# AM335x register map
Vendor: Texas Instruments; Series: Sitara AM335x; File version: 1.1
CPU: Cortex-A8 r0p0, little endian
Registers are 32-bit, read-write, reset 0x0 unless marked. A register's access mark holds for its fields unless they carry their own. Offsets are from the block's base; [hi:lo] are bit positions; {n}, {i} and the like mark numbered series; 'fields as' and 'values as' point back to an identical list.

## EDMACC — EDMA channel controller module
Base 0x49000000
0x00 PID — PIDCC Register
  [15:0] PID — bits 0..15 (R) Peripheral identifier uniquely identifies the EDMA3CC and the
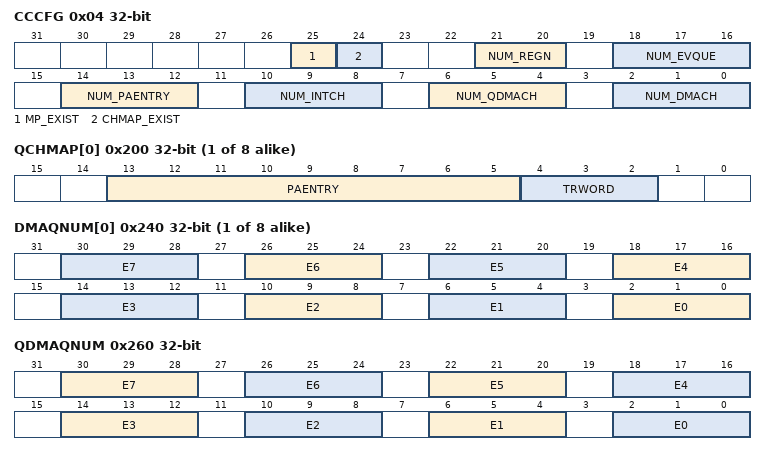
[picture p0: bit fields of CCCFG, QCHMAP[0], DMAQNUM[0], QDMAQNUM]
0x04 CCCFG
  [25] MP_EXIST — bit 25 (R) Memory protection existence
  [24] CHMAP_EXIST — bit 24 (R) Channel map existence
  [21:20] NUM_REGN — bits 20,21 (R) Number of regions
  [18:16] NUM_EVQUE — bits 16..18 (R) Number of event queues
  [14:12] NUM_PAENTRY — bits 12..14 (R) Number of parameter entries
  [10:8] NUM_INTCH — bits 8..10 (R) Number of interrupt channels
  [6:4] NUM_QDMACH — bits 4..6 (R) Number of QDMA channels
  [2:0] NUM_DMACH — bits 0..2 (R) Number of DMA channels
0x10 SYSCONFIG — SYSCONFIGCC Register
  [3:2] IDLEMODE — bits 2,3 (RW) Idle mode configuration [ see e_IDLEMODE]
{0x100+4i} DCHMAP[{i}] (i=0..63) — DMA Channel Mapping Register 0..63
  [13:5] PAENTRY — Parameter entry number
{0x200+4i} QCHMAP[{i}] (i=0..7) — QDMA Channel Mapping Register 0..7
  [13:5] PAENTRY — Parameter entry number
  [4:2] TRWORD — Trigger word selection
{0x240+4i} DMAQNUM[{i}] (i=0..7) — DMA Queue Number Register 0..7
  [4n+2:4n] E{n} (n=0..7)
0x260 QDMAQNUM
  [30:28] E7 — bits 28..30 (RW) Event queue number for QDMA channel 7 [see e_EVENT_QUEUE]
  [26:24] E6 — bits 24..26 (RW) Event queue number for QDMA channel 6 [see e_EVENT_QUEUE]
  [22:20] E5 — bits 20..22 (RW) Event queue number for QDMA channel 5 [see e_EVENT_QUEUE]
  [18:16] E4 — bits 16..18 (RW) Event queue number for QDMA channel 4 [see e_EVENT_QUEUE]
  [14:12] E3 — bits 12..14 (RW) Event queue number for QDMA channel 3 [see e_EVENT_QUEUE]
  [10:8] E2 — bits 8..10 (RW) Event queue number for QDMA channel 2 [see e_EVENT_QUEUE]
  [6:4] E1 — bits 4..6 (RW) Event queue number for QDMA channel 1 [see e_EVENT_QUEUE]
  [2:0] E0 — bits 0..2 (RW) Event queue number for QDMA channel 0 [see e_EVENT_QUEUE]
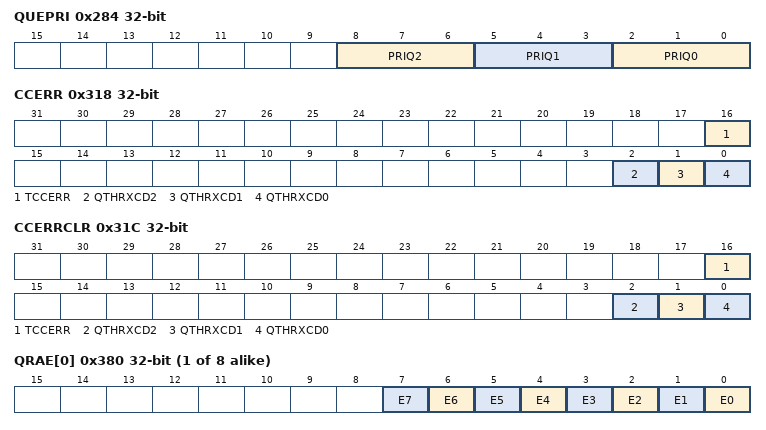
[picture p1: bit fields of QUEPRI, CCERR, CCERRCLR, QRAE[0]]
0x284 QUEPRI
  [8:6] PRIQ2 — bits:8..10 (R/W) Priority level for queue 2. Dictates the priority level used by TC2 relative to other
  [5:3] PRIQ1 — bits:4..6 (R/W) Priority level for queue 1. Dictates the priority level used by TC1 relative to other
  [2:0] PRIQ0 — bits:0..2 (R/W) Priority level for queue 0. Dictates the priority level used by TC0 relative to other
0x300 EMR
  [31:0] En — bits 0..31 (R) Channel 0 to 31 event missed. En is cleared by writing a 1 to the corresponding bit in
0x304 EMRH
  [31:0] En — bits 0..31 (R) Channel 32 to 63 event missed. En is cleared by writing a 1 to the corresponding bit in
0x308 EMCR
  [31:0] En — bits:0..31 (W) Event missed 0 to 31 clear. All error bits must be cleared before additional error
0x30C EMCRH
  [31:0] En — bits:0..31 (W) Event missed 32 to 63 clear. All error bits must be cleared before additional error
0x310 QEMR
  [7:0] En — bits:0..7 (R) Channel 0 to 7 QDMA event missed. En is cleared by writing a 1 to the corresponding bit
0x314 QEMCR
  [7:0] En — bits:0..7 (W) QDMA event missed clear. All error bits must be cleared before additional error
0x318 CCERR
  [16] TCCERR — bit 16 (R) Transfer completion code error
  [2] QTHRXCD2 — bit 2 (R) Queue 2 threshold exceeded error
  [1] QTHRXCD1 — bit 1 (R) Queue 1 threshold exceeded error
  [0] QTHRXCD0 — bit 0 (R) Queue 0 threshold exceeded error
0x31C CCERRCLR
  [16] TCCERR — bit 16 (W) Transfer completion code error clear
  [2] QTHRXCD2 — bit 2 (W) Queue 2 threshold exceeded error clear
  [1] QTHRXCD1 — bit 1 (W) Queue 1 threshold exceeded error clear
  [0] QTHRXCD0 — bit 0 (W) Queue 0 threshold exceeded error clear
0x320 EEVAL
  [0] EVAL — bit 0 (W) Error interrupt evaluate.
{0x340+8i} DRAE{i} (i=0..7) — DRAE Register
  [31:0] En — bits 0..31
{0x344+8i} DRAEH{i} (i=0..7) — DRAEH Register
  [31:0] En — bits:0..31 (R/W) DMA region access enable for bit 63 to 32 in region 0.
{0x380+4i} QRAE[{i}] (i=0..7) — QDMA Region Access Enable Register 0..7
  [n] E{n} (n=0..7) — QDMA channel {n} region access enable
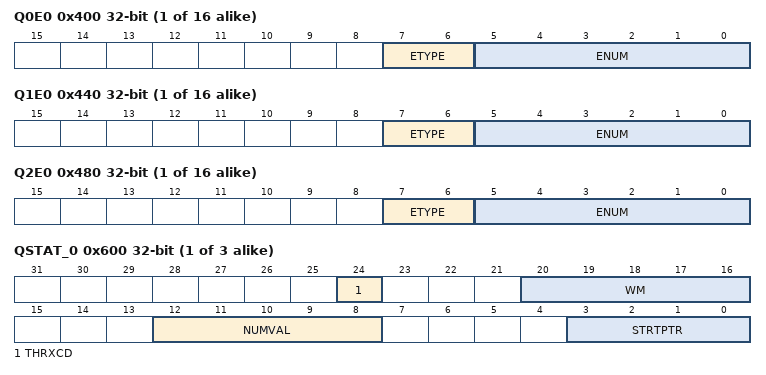
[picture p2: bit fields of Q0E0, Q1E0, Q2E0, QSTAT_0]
{0x400+4i} Q0E{i} (i=0..15) — QmEn Register
  [7:6] ETYPE — bits 6,7 (R) Event entry 0 in queue 1. Specifies the specific event type for the given entry in the
  [5:0] ENUM — bits 0..5 (R) Events entry n(0..15) in queues m(0..3).
{0x440+4i} Q1E{i} (i=0..15) — QmEn Register
  fields as Q0E0
{0x480+4i} Q2E{i} (i=0..15) — QmEn Register
  fields as Q0E0
{0x600+4i} QSTAT_{i} (i=0..2) — QSTAT Register
  [24] THRXCD — bit 24 (R) Threshold crossed.Indicates if the queue threshold was crossed.
  [20:16] WM — bits 16..20 (R) Watermark level.Indicates the watermark level of the queue.
  [12:8] NUMVAL — bits 8..12 (R) Number of valid entries
  [3:0] STRTPTR — bits 0..3 (R) Start pointer.Indicates the start of the queue.
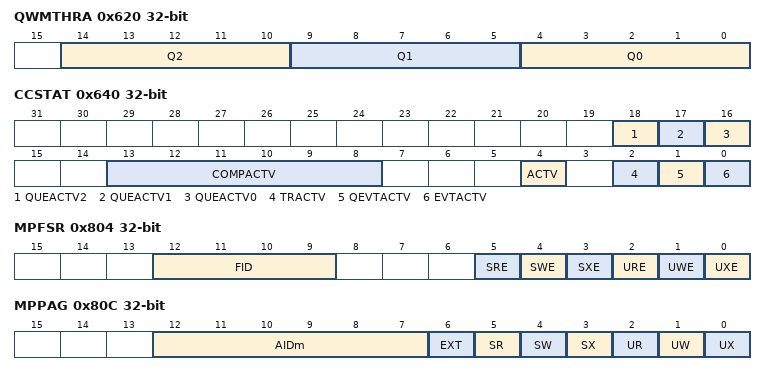
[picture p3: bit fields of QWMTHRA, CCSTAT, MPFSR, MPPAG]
0x620 QWMTHRA
  [14:10] Q2 — bits 16..20 (RW) Watermark threshold for queue 2
  [9:5] Q1 — bits 8..12 (RW) Watermark threshold for queue 1
  [4:0] Q0 — bits 0..4 (RW) Watermark threshold for queue 0
0x640 CCSTAT
  [18] QUEACTV2 — bit 18 (R) Queue 2 active
  [17] QUEACTV1 — bit 17 (R) Queue 1 active
  [16] QUEACTV0 — bit 16 (R) Queue 0 active
  [13:8] COMPACTV — bits 8..13 (R) Completion request active.
  [4] ACTV — bit 4 (R) Channel controller active.
  [2] TRACTV — bit 2 (R) Transfer active
  [1] QEVTACTV — bit 1 (R) QDMA event active
  [0] EVTACTV — bit 0 (R) Event active
0x800 MPFAR
  [31:0] FADDR — bits 0..31 (R) Fault address
0x804 MPFSR
  [12:9] FID — bits 9..12 (R) Faulted identification.
  [5] SRE — bit 5 (R) Supervisor read fault
  [4] SWE — bit 4 (R) Supervisor write fault
  [3] SXE — bit 3 (R) Supervisor execute fault
  [2] URE — bit 2 (R) User read fault
  [1] UWE — bit 1 (R) User write fault
  [0] UXE — bit 0 (R) User execute fault
0x808 MPFCR
  [0] MPFCLR — bit 0 (W) Memory protection fault clear
0x80C MPPAG
  [12:7] AIDm — Access ID mask
  [6] EXT — bit: 9 (RW) Extended attribute
  [5] SR — bit: 5 (RW) Supervisor read permission
  [4] SW — bit: 4 (RW) Supervisor write permission
  [3] SX — bit: 3 (RW) Supervisor execute permission
  [2] UR — bit: 2 (RW) User read permission
  [1] UW — bit: 1 (RW) User write permission
  [0] UX — bit: 0 (RW) User execute permission
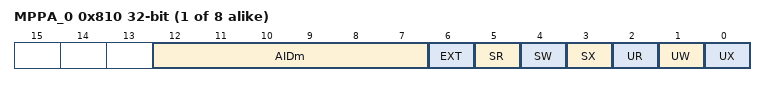
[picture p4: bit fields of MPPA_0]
{0x810+4i} MPPA_{i} (i=0..7) — MPPA Register
  fields as MPPAG
0x1000 ER
  [31:0] En ro — Event 0 to 31.
0x1004 ERH
  [31:0] En ro — Event pending status
0x1008 ECR
  [31:0] En wo — Event clear for event 0 to 31.
0x100C ECRH
  [31:0] En wo — Event clear control
0x1010 ESR
  [31:0] En — Event set for event 0 to 31.
0x1014 ESRH
  [31:0] En — Event set for event 32 to 63.
0x1018 CER
  [31:0] En — Chained event for event 0 to 31.
0x101C CERH
  [31:0] En ro — Chained event set for event 32 to 63.
0x1020 EER
  [31:0] En ro — Event enable for events 0 to 31.
0x1024 EERH
  [31:0] En ro — Event enable for events 32 to 63.
0x1028 EECR
  [31:0] En wo — Event enable clear for events 0 to 31.
0x102C EECRH
  [31:0] En wo — Event enable clear for events 32 to 63.
0x1030 EESR
  [31:0] En wo — Event enable set for events 0 to 31.
0x1034 EESRH
  [31:0] En wo — Event enable set for events 32 to 63.
0x1038 SER
  [31:0] En ro — Secondary event register.
0x103C SERH
  [31:0] En ro — Secondary event register.
0x1040 SECR
  [31:0] En wo — Secondary event clear register.
0x1044 SECRH
  [31:0] En wo — Secondary event clear register.
0x1050 IER
  [31:0] In_ ro — Interrupt enable for channels 0 to 31.
0x1054 IERH
  [31:0] In ro — Interrupt enable for channels 32 to 63.
0x1058 IECR
  [31:0] In ro — Interrupt enable clear for channels 0 to 31.
0x105C IECRH
  [31:0] In wo — Interrupt enable clear for channels 32 to 63.
0x1060 IESR
  [31:0] In wo — Interrupt enable set for channels 0 to 31.
0x1064 IESRH
  [31:0] In wo — Interrupt enable clear for channels 32 to 63.
0x1068 IPR
  [31:0] In ro — Interrupt pending for TCC = 0 to 31.
0x106C IPRH
  [31:0] In ro — Interrupt pending for TCC = 32 to 63.
0x1070 ICR
  [31:0] In wo — Interrupt clear register for TCC = 0 to 31.
0x1074 ICRH
  [31:0] In wo — Interrupt clear register for TCC = 32 to 63.
0x1078 IEVAL
  [0] EVAL — bit: 0 (W) Interrupt evaluate.
0x1080 QER
  [7:0] En ro — QDMA event for channels 0 to 7.
0x1084 QEER
  [7:0] En ro — QDMA event enable for channels 0 to 7.
0x1088 QEECR
  [7:0] En ro — QDMA event enable clear for channels 0 to 7.
0x108C QEESR
  [7:0] En ro — QDMA event enable set for channels 0 to 7.
0x1090 QSER
  [7:0] En ro — QDMA secondary event register for channels 0 to 7.
0x1094 QSECR
  [7:0] En wo — QDMA secondary event clear register for channels 0 to 7.
